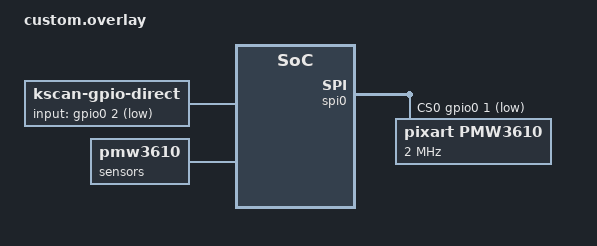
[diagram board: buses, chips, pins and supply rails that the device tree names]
/ {
    chosen {
        zmk,kscan = &kscan0;
    };

    kscan0: kscan {
        compatible = "zmk,kscan-gpio-direct";
        label = "KSCAN";
        input-gpios = <&gpio0 2 (GPIO_ACTIVE_LOW | GPIO_PULL_UP)>;
    };

    sensors {
        compatible = "zmk,pmw3610";
        cs-gpios = <&gpio0 1 GPIO_ACTIVE_LOW>;
    };
};

&spi0 {
    status = "okay";
    compatible = "nordic,nrf-spim";
    pinctrl-0 = <&spi0_default>;
    pinctrl-1 = <&spi0_sleep>;
    pinctrl-names = "default", "sleep";

    cs-gpios = <&gpio0 1 GPIO_ACTIVE_LOW>;

    pmw3610@0 {
        compatible = "pixart,pmw3610";
        reg = <0>;
        spi-max-frequency = <2000000>;
    };
};
